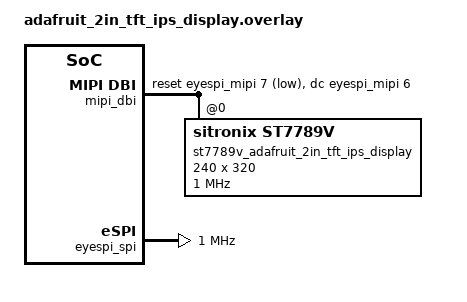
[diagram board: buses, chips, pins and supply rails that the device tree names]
/*
 * SPDX-FileCopyrightText: Copyright 2025 Sam Blenny
 * SPDX-License-Identifier: Apache-2.0
 *
 * Related docs & reference code:
 * - https://docs.zephyrproject.org/latest/build/dts/api/bindings/mipi-dbi/zephyr%2Cmipi-dbi-spi.html
 * - https://docs.zephyrproject.org/4.0.0/build/dts/api/bindings/display/sitronix%2Cst7789v.html
 * - https://newhavendisplay.com/content/datasheets/ST7789V.pdf
 * - https://github.com/adafruit/Adafruit_CircuitPython_ST7789/blob/1.6.4/adafruit_st7789.py
 * - https://github.com/adafruit/circuitpython/blob/main/shared-bindings/busdisplay/BusDisplay.c
 * - https://github.com/adafruit/circuitpython/blob/main/shared-module/busdisplay/BusDisplay.c
 * - https://docs.circuitpython.org/en/latest/shared-bindings/busdisplay/
 * - https://learn.adafruit.com/2-0-inch-320-x-240-color-ips-tft-display/circuitpython-displayio-quickstart
 *
 */

#include <zephyr/dt-bindings/mipi_dbi/mipi_dbi.h>

&eyespi_spi {
	/* Board def probably has wrong cs-gpios, so set it properly */
	cs-gpios = <&eyespi_mipi 8 GPIO_ACTIVE_LOW>;
	/* Datasheet: min serial clock write cycle is 66 ns (15.15 MHz) */
	clock-frequency = <1000000>; /* 1 MHz */
};

/ {
	chosen {
		zephyr,display = &st7789v_adafruit_2in_tft_ips_display;
	};

	mipi_dbi {
		compatible = "zephyr,mipi-dbi-spi";

		/* Configure spi device with DC and reset pins */
		spi-dev = <&eyespi_spi>;
		dc-gpios = <&eyespi_mipi 6 GPIO_ACTIVE_HIGH>;
		reset-gpios = <&eyespi_mipi 7 GPIO_ACTIVE_LOW>;
		write-only;

		#address-cells = <1>;
		#size-cells = <0>;

		st7789v_adafruit_2in_tft_ips_display: st7789v@0 {
			compatible = "sitronix,st7789v";
			reg = <0>;
			mipi-max-frequency = <1000000>; /* 1 MHz */
			mipi-mode = "MIPI_DBI_MODE_SPI_4WIRE";
			x-offset = <0>;
			y-offset = <0>;
			height = <320>;  /* Y range is 0..319 */
			width  = <240>;  /* X range is 0..239 */

			/* These values copied from CircuitPython init sequence */
			colmod   = <0x55>;  /* 16-bit 5-6-5 */
			mdac     = <0x0C>;

			/* Set required properties to defaults from ST7789V datasheet */
			vcom     = <0x20>;
			gctrl    = <0x35>;
			lcm      = <0x2C>;
			gamma    = <0x01>;
			porch-param   = [0C 0C 00 33 33];
			cmd2en-param  = [5A 69 02 00];
			pwctrl1-param = [A4 81];
			pvgam-param   = [d0 00 02 07 0b 1a 31 54 40 29 12 12 12 17];
			nvgam-param   = [d0 00 02 07 05 25 2d 44 44 1c 18 16 1c 1d];
			ram-param     = [00 f0];
			rgb-param     = [40 02 14];
		};
	};
};
